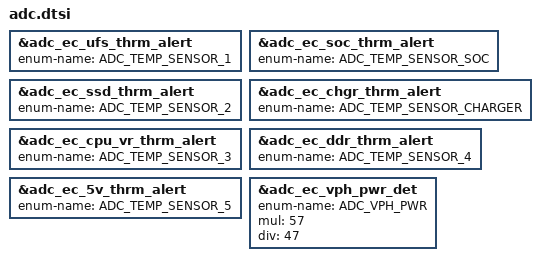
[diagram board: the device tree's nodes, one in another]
/* Copyright 2026 The ChromiumOS Authors
 * Use of this source code is governed by a BSD-style license that can be
 * found in the LICENSE file.
 */

&adc_ec_ufs_thrm_alert {
	enum-name = "ADC_TEMP_SENSOR_1";
};

&adc_ec_soc_thrm_alert {
	enum-name = "ADC_TEMP_SENSOR_SOC";
};

&adc_ec_ssd_thrm_alert {
	enum-name = "ADC_TEMP_SENSOR_2";
};

&adc_ec_chgr_thrm_alert {
	enum-name = "ADC_TEMP_SENSOR_CHARGER";
};

&adc_ec_cpu_vr_thrm_alert {
	enum-name = "ADC_TEMP_SENSOR_3";
};

&adc_ec_ddr_thrm_alert {
	enum-name = "ADC_TEMP_SENSOR_4";
};

&adc_ec_5v_thrm_alert {
	enum-name = "ADC_TEMP_SENSOR_5";
};

&adc_ec_vph_pwr_det {
	enum-name = "ADC_VPH_PWR";
	/* Measured VPH power through 470K / (100K + 470K) voltage divider */
	mul = <57>;
	div = <47>;
};
